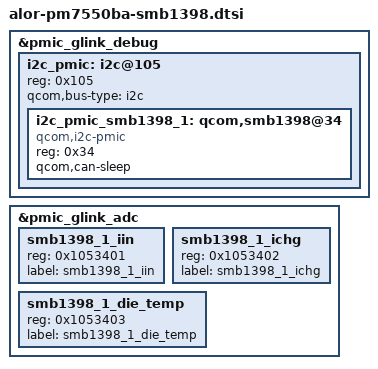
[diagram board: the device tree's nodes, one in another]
// SPDX-License-Identifier: BSD-3-Clause
/*
 * Copyright (c) Qualcomm Technologies, Inc. and/or its subsidiaries.
 */

#include "alor-pm7550ba-pmd802x.dtsi"

&pmic_glink_debug {
	i2c_pmic:i2c@105 {
		reg = <0x105>;  /* I2C instance 5 in ADSP for SE4 */
		#address-cells = <1>;
		#size-cells = <0>;
		qcom,bus-type = "i2c";

		i2c_pmic_smb1398_1: qcom,smb1398@34 {
			compatible = "qcom,i2c-pmic";
			reg = <0x34>;
			qcom,can-sleep;
		};
	};
};

&pmic_glink_adc {
	status = "ok";

	smb1398_1_iin {
		reg = <0x1053401>;
		label = "smb1398_1_iin";
	};

	smb1398_1_ichg {
		reg = <0x1053402>;
		label = "smb1398_1_ichg";
	};

	smb1398_1_die_temp {
		reg = <0x1053403>;
		label = "smb1398_1_die_temp";
	};
};
